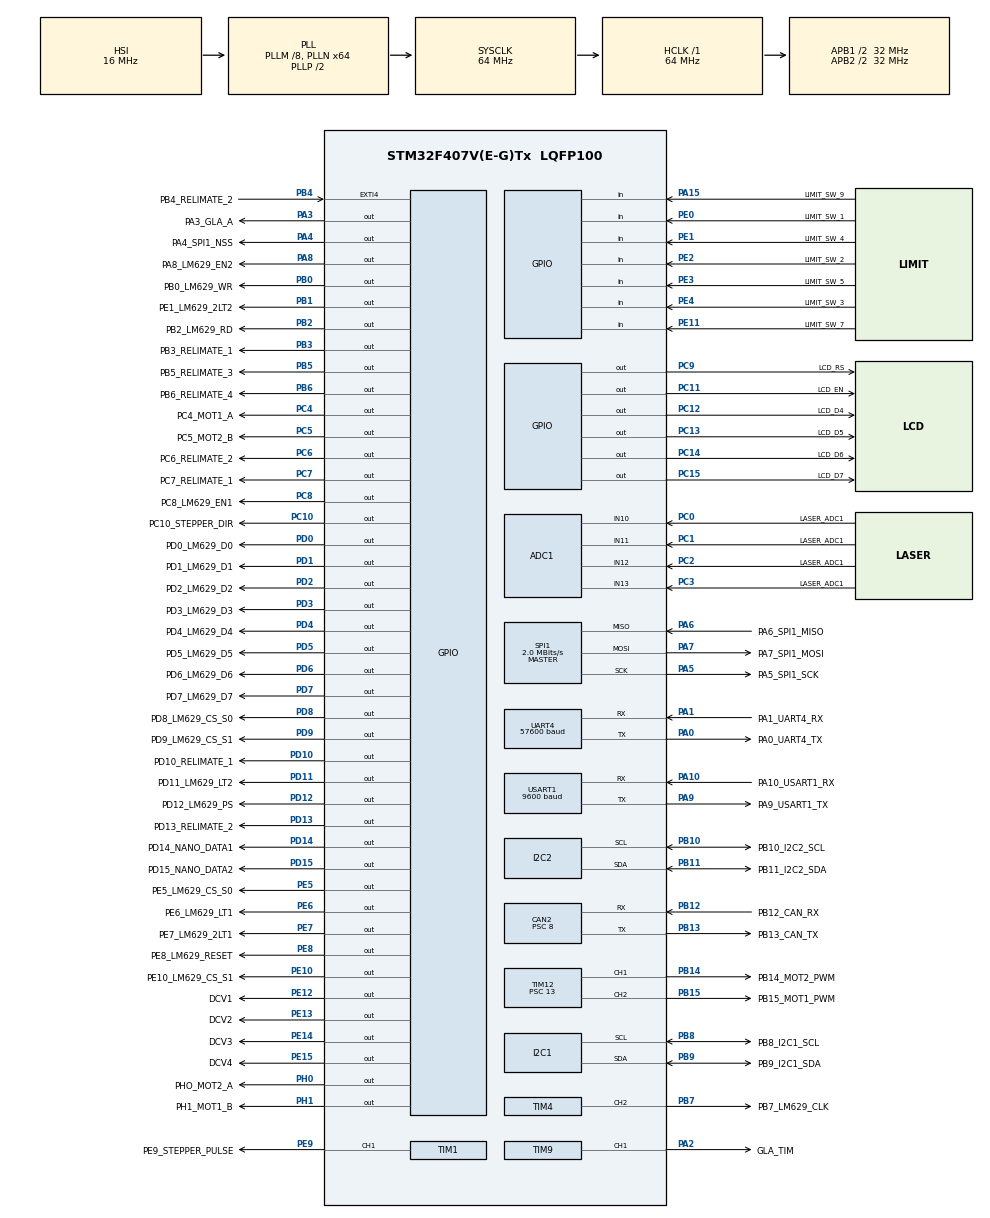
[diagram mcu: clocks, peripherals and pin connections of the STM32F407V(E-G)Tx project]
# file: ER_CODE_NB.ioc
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ADC1.Channel-4\#ChannelRegularConversion=ADC_CHANNEL_10
ADC1.Channel-5\#ChannelRegularConversion=ADC_CHANNEL_10
ADC1.Channel-6\#ChannelRegularConversion=ADC_CHANNEL_10
ADC1.NbrOfConversion=3
ADC1.NbrOfConversionFlag=1
ADC1.Rank-4\#ChannelRegularConversion=1
ADC1.Rank-5\#ChannelRegularConversion=2
ADC1.Rank-6\#ChannelRegularConversion=3
ADC1.SamplingTime-4\#ChannelRegularConversion=ADC_SAMPLETIME_3CYCLES
ADC1.SamplingTime-5\#ChannelRegularConversion=ADC_SAMPLETIME_3CYCLES
ADC1.SamplingTime-6\#ChannelRegularConversion=ADC_SAMPLETIME_3CYCLES
ADC1.ScanConvMode=ENABLE
ADC1.master=1
CAN2.BS1=CAN_BS1_13TQ
CAN2.BS2=CAN_BS2_2TQ
CAN2.CalculateBaudRate=250000
CAN2.CalculateTimeBit=4000
CAN2.CalculateTimeQuantum=250.0
CAN2.Prescaler=8
Dma.Request0=UART4_RX
Dma.Request1=UART4_TX
Dma.UART4_RX.0.Direction=DMA_PERIPH_TO_MEMORY
Dma.UART4_RX.0.FIFOMode=DMA_FIFOMODE_DISABLE
Dma.UART4_RX.0.Instance=DMA1_Stream2
Dma.UART4_RX.0.MemDataAlignment=DMA_MDATAALIGN_BYTE
Dma.UART4_RX.0.MemInc=DMA_MINC_ENABLE
Dma.UART4_RX.0.Mode=DMA_NORMAL
Dma.UART4_RX.0.PeriphDataAlignment=DMA_PDATAALIGN_BYTE
Dma.UART4_RX.0.PeriphInc=DMA_PINC_DISABLE
Dma.UART4_RX.0.Priority=DMA_PRIORITY_LOW
Dma.UART4_TX.1.Direction=DMA_MEMORY_TO_PERIPH
Dma.UART4_TX.1.FIFOMode=DMA_FIFOMODE_DISABLE
Dma.UART4_TX.1.Instance=DMA1_Stream4
Dma.UART4_TX.1.MemDataAlignment=DMA_MDATAALIGN_BYTE
Dma.UART4_TX.1.MemInc=DMA_MINC_ENABLE
Dma.UART4_TX.1.Mode=DMA_NORMAL
Dma.UART4_TX.1.PeriphDataAlignment=DMA_PDATAALIGN_BYTE
Dma.UART4_TX.1.PeriphInc=DMA_PINC_DISABLE
Dma.UART4_TX.1.Priority=DMA_PRIORITY_LOW
I2C2.I2C_Mode=I2C_Fast
Mcu.Family=STM32F4
Mcu.Name=STM32F407V(E-G)Tx
Mcu.Package=LQFP100
NVIC.DMA1_Stream2_IRQn=true\:0\:0\:false\:false\:true\:false\:true\:true
NVIC.DMA1_Stream4_IRQn=true\:0\:0\:false\:false\:true\:false\:true\:true
NVIC.PriorityGroup=NVIC_PRIORITYGROUP_4
NVIC.USART1_IRQn=true\:0\:0\:false\:false\:true\:true\:true\:true
PA0-WKUP.GPIO_Label=PA0_UART4_TX
PA0-WKUP.Mode=Asynchronous
PA0-WKUP.Signal=UART4_TX
PA1.GPIO_Label=PA1_UART4_RX
PA1.Mode=Asynchronous
PA1.Signal=UART4_RX
PA10.GPIO_Label=PA10_USART1_RX
PA10.Mode=Asynchronous
PA10.Signal=USART1_RX
PA13.Mode=Serial_Wire
PA13.Signal=SYS_JTMS-SWDIO
PA14.Mode=Serial_Wire
PA14.Signal=SYS_JTCK-SWCLK
PA15.GPIO_Label=LIMIT_SW_9
PA15.Signal=GPIO_Input
PA2.GPIO_Label=GLA_TIM
PA2.Signal=S_TIM9_CH1
PA3.GPIO_Label=PA3_GLA_A
PA3.Signal=GPIO_Output
PA4.GPIO_Label=PA4_SPI1_NSS
PA4.Signal=GPIO_Output
PA5.GPIO_Label=PA5_SPI1_SCK
PA5.Mode=Full_Duplex_Master
PA5.Signal=SPI1_SCK
PA6.GPIO_Label=PA6_SPI1_MISO
PA6.Mode=Full_Duplex_Master
PA6.Signal=SPI1_MISO
PA7.GPIO_Label=PA7_SPI1_MOSI
PA7.Mode=Full_Duplex_Master
PA7.Signal=SPI1_MOSI
PA8.GPIO_Label=PA8_LM629_EN2
PA8.Signal=GPIO_Output
PA9.GPIO_Label=PA9_USART1_TX
PA9.Mode=Asynchronous
PA9.Signal=USART1_TX
PB0.GPIO_Label=PB0_LM629_WR
PB0.Signal=GPIO_Output
PB1.GPIO_Label=PE1_LM629_2LT2
PB1.Signal=GPIO_Output
PB10.GPIO_Label=PB10_I2C2_SCL
PB10.Mode=I2C
PB10.Signal=I2C2_SCL
PB11.GPIO_Label=PB11_I2C2_SDA
PB11.Mode=I2C
PB11.Signal=I2C2_SDA
PB12.GPIO_Label=PB12_CAN_RX
PB12.Mode=CAN_Activate
PB12.Signal=CAN2_RX
PB13.GPIO_Label=PB13_CAN_TX
PB13.Mode=CAN_Activate
PB13.Signal=CAN2_TX
PB14.GPIO_Label=PB14_MOT2_PWM
PB14.Signal=S_TIM12_CH1
PB15.GPIO_Label=PB15_MOT1_PWM
PB15.Signal=S_TIM12_CH2
PB2.GPIO_Label=PB2_LM629_RD
PB2.Signal=GPIO_Output
PB3.GPIO_Label=PB3_RELIMATE_1
PB3.Signal=GPIO_Output
PB4.GPIO_Label=PB4_RELIMATE_2
PB4.Signal=GPXTI4
PB5.GPIO_Label=PB5_RELIMATE_3
PB5.Signal=GPIO_Output
PB6.GPIO_Label=PB6_RELIMATE_4
PB6.Signal=GPIO_Output
PB7.GPIO_Label=PB7_LM629_CLK
PB7.Signal=S_TIM4_CH2
PB8.GPIO_Label=PB8_I2C1_SCL
PB8.Mode=I2C
PB8.Signal=I2C1_SCL
PB9.GPIO_Label=PB9_I2C1_SDA
PB9.Mode=I2C
PB9.Signal=I2C1_SDA
PC0.GPIO_Label=LASER_ADC1
PC0.Signal=ADCx_IN10
PC1.GPIO_Label=LASER_ADC1
PC1.Signal=ADCx_IN11
PC10.GPIO_Label=PC10_STEPPER_DIR
PC10.Signal=GPIO_Output
PC11.GPIO_Label=LCD_EN
PC11.Signal=GPIO_Output
PC12.GPIO_Label=LCD_D4
PC12.Signal=GPIO_Output
PC13-ANTI_TAMP.GPIO_Label=LCD_D5
PC13-ANTI_TAMP.Signal=GPIO_Output
PC14-OSC32_IN.GPIO_Label=LCD_D6
PC14-OSC32_IN.Signal=GPIO_Output
PC15-OSC32_OUT.GPIO_Label=LCD_D7
PC15-OSC32_OUT.Signal=GPIO_Output
PC2.GPIO_Label=LASER_ADC1
PC2.Signal=ADCx_IN12
PC3.GPIO_Label=LASER_ADC1
PC3.Signal=ADCx_IN13
PC4.GPIO_Label=PC4_MOT1_A
PC4.Signal=GPIO_Output
PC5.GPIO_Label=PC5_MOT2_B
PC5.Signal=GPIO_Output
PC6.GPIO_Label=PC6_RELIMATE_2
PC6.Signal=GPIO_Output
PC7.GPIO_Label=PC7_RELIMATE_1
PC7.Signal=GPIO_Output
PC8.GPIO_Label=PC8_LM629_EN1
PC8.Signal=GPIO_Output
PC9.GPIO_Label=LCD_RS
PC9.Signal=GPIO_Output
PD0.GPIO_Label=PD0_LM629_D0
PD0.Signal=GPIO_Output
PD1.GPIO_Label=PD1_LM629_D1
PD1.Signal=GPIO_Output
PD10.GPIO_Label=PD10_RELIMATE_1
PD10.Signal=GPIO_Output
PD11.GPIO_Label=PD11_LM629_LT2
PD11.Signal=GPIO_Output
PD12.GPIO_Label=PD12_LM629_PS
PD12.Signal=GPIO_Output
PD13.GPIO_Label=PD13_RELIMATE_2
PD13.Signal=GPIO_Output
PD14.GPIO_Label=PD14_NANO_DATA1
PD14.Signal=GPIO_Output
PD15.GPIO_Label=PD15_NANO_DATA2
PD15.Signal=GPIO_Output
PD2.GPIO_Label=PD2_LM629_D2
PD2.Signal=GPIO_Output
PD3.GPIO_Label=PD3_LM629_D3
PD3.Signal=GPIO_Output
PD4.GPIO_Label=PD4_LM629_D4
PD4.Signal=GPIO_Output
PD5.GPIO_Label=PD5_LM629_D5
PD5.Signal=GPIO_Output
PD6.GPIO_Label=PD6_LM629_D6
PD6.Signal=GPIO_Output
PD7.GPIO_Label=PD7_LM629_D7
PD7.Signal=GPIO_Output
PD8.GPIO_Label=PD8_LM629_CS_S0
PD8.Signal=GPIO_Output
PD9.GPIO_Label=PD9_LM629_CS_S1
PD9.Signal=GPIO_Output
PE0.GPIO_Label=LIMIT_SW_1
PE0.Signal=GPIO_Input
PE1.GPIO_Label=LIMIT_SW_4
PE1.Signal=GPIO_Input
PE10.GPIO_Label=PE10_LM629_CS_S1
PE10.Signal=GPIO_Output
PE11.GPIO_Label=LIMIT_SW_7
PE11.Signal=GPIO_Input
PE12.GPIO_Label=DCV1
PE12.Signal=GPIO_Output
PE13.GPIO_Label=DCV2
PE13.Signal=GPIO_Output
PE14.GPIO_Label=DCV3
PE14.Signal=GPIO_Output
PE15.GPIO_Label=DCV4
PE15.Signal=GPIO_Output
PE2.GPIO_Label=LIMIT_SW_2
PE2.Signal=GPIO_Input
PE3.GPIO_Label=LIMIT_SW_5
PE3.Signal=GPIO_Input
PE4.GPIO_Label=LIMIT_SW_3
PE4.Signal=GPIO_Input
PE5.GPIO_Label=PE5_LM629_CS_S0
PE5.Signal=GPIO_Output
PE6.GPIO_Label=PE6_LM629_LT1
PE6.Signal=GPIO_Output
PE7.GPIO_Label=PE7_LM629_2LT1
PE7.Signal=GPIO_Output
PE8.GPIO_Label=PE8_LM629_RESET
PE8.Signal=GPIO_Output
PE9.GPIO_Label=PE9_STEPPER_PULSE
PE9.Signal=S_TIM1_CH1
PH0-OSC_IN.GPIO_Label=PHO_MOT2_A
PH0-OSC_IN.Signal=GPIO_Output
PH1-OSC_OUT.GPIO_Label=PH1_MOT1_B
PH1-OSC_OUT.Signal=GPIO_Output
ProjectManager.HeapSize=0x200
ProjectManager.StackSize=0x400
ProjectManager.TargetToolchain=STM32CubeIDE
RCC.48MHZClocksFreq_Value=32000000
RCC.AHBFreq_Value=64000000
RCC.APB1CLKDivider=RCC_HCLK_DIV2
RCC.APB1Freq_Value=32000000
RCC.APB1TimFreq_Value=64000000
RCC.APB2CLKDivider=RCC_HCLK_DIV2
RCC.APB2Freq_Value=32000000
RCC.APB2TimFreq_Value=64000000
RCC.CortexFreq_Value=64000000
RCC.HCLKFreq_Value=64000000
RCC.HSE_VALUE=25000000
RCC.HSI_VALUE=16000000
RCC.LSE_VALUE=32768
RCC.PLLM=8
RCC.PLLN=64
RCC.SYSCLKFreq_VALUE=64000000
RCC.SYSCLKSource=RCC_SYSCLKSOURCE_PLLCLK
RCC.VCOOutputFreq_Value=128000000
SH.ADCx_IN10.0=ADC1_IN10,IN10
SH.ADCx_IN11.0=ADC1_IN11,IN11
SH.ADCx_IN12.0=ADC1_IN12,IN12
SH.ADCx_IN13.0=ADC1_IN13,IN13
SH.S_TIM12_CH1.0=TIM12_CH1,PWM Generation1 CH1
SH.S_TIM12_CH2.0=TIM12_CH2,PWM Generation2 CH2
SH.S_TIM1_CH1.0=TIM1_CH1,PWM Generation1 CH1
SH.S_TIM4_CH2.0=TIM4_CH2,Output Compare2 CH2
SH.S_TIM9_CH1.0=TIM9_CH1,PWM Generation1 CH1
SPI1.BaudRatePrescaler=SPI_BAUDRATEPRESCALER_16
SPI1.CalculateBaudRate=2.0 MBits/s
SPI1.Direction=SPI_DIRECTION_2LINES
SPI1.Mode=SPI_MODE_MASTER
SPI1.VirtualType=VM_MASTER
TIM1.Channel-PWM\ Generation1\ CH1=TIM_CHANNEL_1
TIM1.Period=255
TIM1.Prescaler=13
TIM12.Channel-PWM\ Generation1\ CH1=TIM_CHANNEL_1
TIM12.Channel-PWM\ Generation2\ CH2=TIM_CHANNEL_2
TIM12.Period=255
TIM12.Prescaler=13
TIM4.Channel-Output\ Compare2\ CH2=TIM_CHANNEL_2
TIM4.OCMode_2=TIM_OCMODE_TOGGLE
TIM4.Period=7
TIM7.Prescaler=7
TIM9.Channel-PWM\ Generation1\ CH1=TIM_CHANNEL_1
TIM9.Period=255
TIM9.Prescaler=13
UART4.BaudRate=57600
UART4.VirtualMode=Asynchronous
USART1.BaudRate=9600
USART1.VirtualMode=VM_ASYNC
VP_TIM7_VS_ClockSourceINT.Mode=Enable_Timer
board=custom

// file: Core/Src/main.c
/* USER CODE BEGIN Header */
/**
 ******************************************************************************
 * @file           : main.c
 * @brief          : Main program body
 ******************************************************************************
 * @attention
 *
 * Copyright (c) 2023 STMicroelectronics.
 * All rights reserved.
 *
 * This software is licensed under terms that can be found in the LICENSE file
 * in the root directory of this software component.
 * If no LICENSE file comes with this software, it is provided AS-IS.
 *
 ******************************************************************************
 */
/* USER CODE END Header */
#include "main.h"
#include "adc.h"
#include "can.h"
#include "dma.h"
#include "i2c.h"
#include "spi.h"
#include "tim.h"
#include "usart.h"
#include "gpio.h"

/* USER CODE BEGIN Includes */
#include "init.h"
/* USER CODE END Includes */

void SystemClock_Config(void);

int main(void)
{

	/* MCU Configuration--------------------------------------------------------*/

	/* Reset of all peripherals, Initializes the Flash interface and the Systick. */
	HAL_Init();

	/* Configure the system clock */
	SystemClock_Config();

	/* Initialize all configured peripherals */
	MX_GPIO_Init();
	MX_DMA_Init();
	MX_UART4_Init();
	MX_USART1_UART_Init();
	MX_ADC1_Init();
	MX_CAN2_Init();
	MX_I2C1_Init();
	MX_I2C2_Init();
	MX_SPI1_Init();
	MX_TIM4_Init();
	MX_TIM12_Init();
	MX_TIM1_Init();
	MX_TIM7_Init();
	MX_TIM9_Init();
	/* USER CODE BEGIN 2 */
	int accnf = 600;
	delay_init(DELAY_MODULE);
	lm629_clock_start(LM629_CLOCK_MODULE);
	motors_pwm_start(MOTOR_MODULE);
	//	encoders_init();
	adc_init();
	mux_auto();
	lcd_init();
	// CAN_filterConfig();
	// HAL_CAN_Start(&hcan2);
	//	servo_pwm_start(BLDC_TIM_MODULE);
	int q, tick, dt, prev_tick, pd;
	int ps4_mode = 0;
	int st = 0;
	int pickmode = 0;
	int mode = 0;
	int limit_value1 = 0;
	int limit_value4 = 0;
	int limit_value3 = 0;
	int limit_value2 = 0;
	char *buffer1[1];
	int ret;
	int stop = 0;
	int j = 800;
	int steppermode = 0;

	lcd_gotoxy(1, 1);
	lcd_string("Robocon 2023");
	HAL_Delay(800);
	lcd_clear();

	int status = 0;
	//		encoders_define_home();
	lcd_clear();
	lcd_gotoxy(1, 1);
	lcd_string("Homed");
	HAL_Delay(800);
	lcd_clear();
	lcd_clear();
	float x = 0;
	float y = 0;

	int prev_distance = 0;
	/////////////////////
	//	    robot_position_init(50,50);
	robot_velocity_init(accnf);
	lcd_clear();
	lcd_gotoxy(1, 1);
	lcd_string("Velocity init done");
	HAL_Delay(800);
	lcd_clear();

	while (pairing_flag == false)
	{
		lcd_gotoxy(4, 1);
		connect_ps4();
		lcd_gotoxy(1, 4);
		lcd_string("Pair Lost");
	}
	lcd_clear();

	stick_invert_flag = false;

	/* USER CODE END 2 */

	/* Infinite loop */
	/* USER CODE BEGIN WHILE */
	while (0)
	{
		VELOCITY_MAX_SPEED = 350;
		receive_ps4();
		lcd_print(1, 1, read_real_position(1), 5);
		lcd_print(2, 1, read_real_position(2), 5);
		lcd_print(3, 1, read_real_position(3), 5);
		lcd_print(4, 1, read_real_position(4), 5);

		lcd_print(4, 10, HAL_GPIO_ReadPin(LIMIT_SW_1_GPIO_Port, LIMIT_SW_1_Pin), 1);
		lcd_print(4, 11, HAL_GPIO_ReadPin(LIMIT_SW_2_GPIO_Port, LIMIT_SW_2_Pin), 1);
		lcd_print(4, 12, HAL_GPIO_ReadPin(LIMIT_SW_3_GPIO_Port, LIMIT_SW_3_Pin), 1);
		lcd_print(4, 13, HAL_GPIO_ReadPin(LIMIT_SW_4_GPIO_Port, LIMIT_SW_4_Pin), 1);
		lcd_print(4, 14, HAL_GPIO_ReadPin(LIMIT_SW_5_GPIO_Port, LIMIT_SW_5_Pin), 1);
		lcd_print(4, 15, HAL_GPIO_ReadPin(LIMIT_SW_7_GPIO_Port, LIMIT_SW_7_Pin), 1);
		lcd_print(4, 16, HAL_GPIO_ReadPin(LIMIT_SW_9_GPIO_Port, LIMIT_SW_9_Pin), 1);
		lcd_print(3, 10, j, 4);

		//	  if (PS4_L1_PRESSED)
		//	  		{
		//		  	  	  robot_newvelocity_run(100, 0, 0, SMOOTH_STOP);
		//	  		}
		//	  if (PS4_L2_PRESSED)
		//	  		{
		//		  	  	  robot_newvelocity_run(0, 0, 0, SMOOTH_STOP);
		//	  		}
		//	  if (PS4_R1_PRESSED)
		//			{
		//				  robot_newvelocity_run(100, 90, 0, SMOOTH_STOP);
		//			}
		//	  if (PS4_R2_PRESSED)
		//			{
		//				  robot_newvelocity_run(0, 0, 45, SMOOTH_STOP);
		//			}
		//	  if (PS4_CROSS_PRESSED)
		//	  			{
		//	  				  robot_newvelocity_run(100,180, 0, SMOOTH_STOP);
		//	  			}
		robot_joystick_velocity();
		SAVE_CONSOLE;
	}
	while (1)
	{
		/* USER CODE END WHILE */

		/* USER CODE BEGIN 3 */

		/////////////////////////

		/////////////////////////

		receive_ps4();
		lcd_print(1, 1, read_real_position(1), 5);
		lcd_print(2, 1, read_real_position(2), 5);
		lcd_print(3, 1, read_real_position(3), 5);
		lcd_print(4, 1, read_real_position(4), 5);

		lcd_print(4, 10, HAL_GPIO_ReadPin(LIMIT_SW_1_GPIO_Port, LIMIT_SW_1_Pin), 1);
		lcd_print(4, 11, HAL_GPIO_ReadPin(LIMIT_SW_2_GPIO_Port, LIMIT_SW_2_Pin), 1);
		lcd_print(4, 12, HAL_GPIO_ReadPin(LIMIT_SW_3_GPIO_Port, LIMIT_SW_3_Pin), 1);
		lcd_print(4, 13, HAL_GPIO_ReadPin(LIMIT_SW_4_GPIO_Port, LIMIT_SW_4_Pin), 1);
		lcd_print(4, 14, HAL_GPIO_ReadPin(LIMIT_SW_5_GPIO_Port, LIMIT_SW_5_Pin), 1);
		lcd_print(4, 15, HAL_GPIO_ReadPin(LIMIT_SW_7_GPIO_Port, LIMIT_SW_7_Pin), 1);
		lcd_print(4, 16, HAL_GPIO_ReadPin(LIMIT_SW_9_GPIO_Port, LIMIT_SW_9_Pin), 1);
		lcd_print(3, 10, j, 4);

		if (HAL_GPIO_ReadPin(GPIOA, GPIO_PIN_10) == 1)
		{
			st = 0;
		}
		if (st > 19)
		{
			st = 19;
		}
		if (st < 0)
		{
			st = 0;
		}

		if (PS4_CROSS_PRESSED)
		{
			robot_velocity_init(accnf);
			lcd_clear();
			lcd_gotoxy(1, 1);
			lcd_string("Velocity INIT Done");
			HAL_Delay(800);
			lcd_clear();
			lcd_print(1, 1, read_real_position(1), 5);
			lcd_print(2, 1, read_real_position(2), 5);
			lcd_print(3, 1, read_real_position(3), 5);
			lcd_print(4, 1, read_real_position(4), 5);

			lcd_print(4, 10, HAL_GPIO_ReadPin(LIMIT_SW_1_GPIO_Port, LIMIT_SW_1_Pin), 1);
			lcd_print(4, 11, HAL_GPIO_ReadPin(LIMIT_SW_2_GPIO_Port, LIMIT_SW_2_Pin), 1);
			lcd_print(4, 12, HAL_GPIO_ReadPin(LIMIT_SW_3_GPIO_Port, LIMIT_SW_3_Pin), 1);
			lcd_print(4, 13, HAL_GPIO_ReadPin(LIMIT_SW_4_GPIO_Port, LIMIT_SW_4_Pin), 1);
			lcd_print(4, 14, HAL_GPIO_ReadPin(LIMIT_SW_5_GPIO_Port, LIMIT_SW_5_Pin), 1);
			lcd_print(3, 10, j, 4);
		}
		//////////////  BD Mode
		if (PS4_L1_PRESSED)
		{
			VELOCITY_MAX_SPEED = 100;
		}

		if (PS4_L1_RELEASED)
		{
			VELOCITY_MAX_SPEED = 400;
		}

		if (PS4_OPTIONS_PRESSED)
		{
			ps4_mode = !(ps4_mode);
			lcd_print(4, 17, ps4_mode, 1);
		}
		if (pickmode == 1)
		{

			if (HAL_GPIO_ReadPin(LIMIT_SW_7_GPIO_Port, LIMIT_SW_7_Pin) == 1)
			{
				mode = 1;
			}
			if (HAL_GPIO_ReadPin(LIMIT_SW_5_GPIO_Port, LIMIT_SW_5_Pin) == 1)
			{
				mode = 0;
			}
			if (HAL_GPIO_ReadPin(LIMIT_SW_1_GPIO_Port, LIMIT_SW_1_Pin) == 1)
			{
				if (mode == 0)
				{
					limit_value1 = 100;
				}
				else
				{
					limit_value1 = 250; // 160
				}
			}
			else
			{
				limit_value1 = 10;
			}

			motor_fwd(ELBOW, limit_value1);
			if (HAL_GPIO_ReadPin(LIMIT_SW_3_GPIO_Port, LIMIT_SW_3_Pin) == 1)
			{
				limit_value4 = 80;
			}
			else
			{
				pickmode = 0;
				limit_value4 = 0;
			}
			motor_rev(SHOULDER, limit_value4);
		}

		if (ps4_mode == 0) // RING PICKING MODE
		{

			////////TURN TABLE   --  SQUARE, CIRCLE
			if (PS4_SQUARE)
			{

				if (HAL_GPIO_ReadPin(LIMIT_SW_3_GPIO_Port, LIMIT_SW_3_Pin) == 0)
				{
					limit_value3 = 100;
				}
				else
				{
					limit_value3 = 0;
				}

				motor_fwd(SHOULDER, limit_value3);
			}
			if (PS4_SQUARE_RELEASED)
			{

				motor_fwd(SHOULDER, 0);
			}

			if (PS4_CIRCLE)
			{

				if (HAL_GPIO_ReadPin(LIMIT_SW_4_GPIO_Port, LIMIT_SW_4_Pin) == 0)
				{
					limit_value4 = 120;
				}
				else
				{
					limit_value4 = 0;
				}
				motor_rev(SHOULDER, limit_value4);
			}
			if (PS4_CIRCLE_RELEASED)
			{

				motor_rev(SHOULDER, 0);
			}
			///////////////////////////////////////////////////////////////////////////
			if (PS4_L1)
			{
				// Turn Table
				if (PS4_SQUARE)
				{
					motor_fwd(SHOULDER, 100);
				}
				if (PS4_SQUARE_RELEASED)
				{
					motor_fwd(SHOULDER, 0);
				}

				if (PS4_CIRCLE)
				{
					motor_rev(SHOULDER, 120);
				}
				if (PS4_CIRCLE_RELEASED)
				{
					motor_rev(SHOULDER, 0);
				}

				// Side Tower
				if (PS4_PAD_UP)
				{
					motor_fwd(ELBOW, 150);
				}
				if (PS4_PAD_UP_RELEASED)
				{
					motor_fwd(ELBOW, 0);
				}
				if (PS4_PAD_DOWN)
				{
					motor_rev(ELBOW, 70);
				}
				if (PS4_PAD_DOWN_RELEASED)
				{
					motor_rev(ELBOW, 0);
				}
			}

			if (PS4_TOUCHPAD_PRESSED) // SIDE TOWER GRIPPER
			{
				HAL_GPIO_TogglePin(DCV2_GPIO_Port, DCV2_Pin);
				HAL_Delay(100);
			}

			if (PS4_TRIANGLE_PRESSED) // SIDE TOWER UP DOWN
			{
				HAL_GPIO_TogglePin(DCV3_GPIO_Port, DCV3_Pin);
			}
			if (PS4_PAD_LEFT_PRESSED) // SIDE TOWER UP DOWN
			{
				HAL_GPIO_TogglePin(DCV4_GPIO_Port, DCV4_Pin);
			}

			////////// SIDE TOWER  -- PAD_UP(up), PAD_DOWN(down) with limit switch

			if (PS4_PAD_UP)
			{
				//				limit_value1 = 100;

				if (HAL_GPIO_ReadPin(LIMIT_SW_1_GPIO_Port, LIMIT_SW_1_Pin) == 0)
				{
					limit_value1 = 150;
				}
				else
				{
					limit_value1 = 30;
				}

				motor_fwd(ELBOW, limit_value1);
			}
			if (PS4_PAD_UP_RELEASED)
			{

				motor_fwd(ELBOW, 0);
			}
			if (PS4_PAD_DOWN)
			{

				if (HAL_GPIO_ReadPin(LIMIT_SW_2_GPIO_Port, LIMIT_SW_2_Pin) == 1)
				{

					limit_value2 = 70;
				}
				else
				{
					limit_value2 = 0;
				}
				motor_rev(ELBOW, limit_value2);
			}
			if (PS4_PAD_DOWN_RELEASED)
			{

				motor_rev(ELBOW, 0);
			}
		}

		if (ps4_mode == 1) // RING SHOOTING MODE
		{
			if (PS4_L1)
			{
				steppermode = 1;
			}
			else
			{
				steppermode = 0;
			}

			if (steppermode == 0)
			{
				if (PS4_PAD_DOWN_PRESSED && (HAL_GPIO_ReadPin(LIMIT_SW_5_GPIO_Port, LIMIT_SW_5_Pin) == 0))
				{
					st--;
					//				if(st >= 0){
					buffer1[0] = '2';
					ret = HAL_I2C_Master_Transmit(&hi2c1, 4 << 1, (uint8_t *)buffer1, 1, 100);
					lcd_gotoxy(1, 10);
					lcd_string("Down");
					//				}
				}
				else if (PS4_PAD_DOWN_RELEASED)
				{
					buffer1[0] = 'a';
					ret = HAL_I2C_Master_Transmit(&hi2c1, 4 << 1, (uint8_t *)buffer1, 1, 100);
				}
				if (PS4_PAD_UP_PRESSED)
				{
					st++;
					//				if(st <= 19){
					buffer1[0] = '1';
					ret = HAL_I2C_Master_Transmit(&hi2c1, 4 << 1, (uint8_t *)buffer1, 1, 100);
					lcd_gotoxy(1, 10);
					lcd_string("Up");
					//				}
				}
				else if (PS4_PAD_UP_RELEASED)
				{
					buffer1[0] = 'a';
					ret = HAL_I2C_Master_Transmit(&hi2c1, 4 << 1, (uint8_t *)buffer1, 1, 100);
				}
			}
			if (steppermode == 1)
			{
				if (PS4_PAD_DOWN_PRESSED && (HAL_GPIO_ReadPin(LIMIT_SW_5_GPIO_Port, LIMIT_SW_5_Pin) == 0))
				{
					st--;
					//				if(st >= 0){
					buffer1[0] = '6';
					ret = HAL_I2C_Master_Transmit(&hi2c1, 4 << 1, (uint8_t *)buffer1, 1, 100);
					lcd_gotoxy(1, 10);
					lcd_string("Down");
					//				}
				}
				else if (PS4_PAD_DOWN_RELEASED)
				{
					buffer1[0] = 'a';
					ret = HAL_I2C_Master_Transmit(&hi2c1, 4 << 1, (uint8_t *)buffer1, 1, 100);
				}
				if (PS4_PAD_UP_PRESSED)
				{
					st++;
					//				if(st <= 19){
					buffer1[0] = '5';
					ret = HAL_I2C_Master_Transmit(&hi2c1, 4 << 1, (uint8_t *)buffer1, 1, 100);
					lcd_gotoxy(1, 10);
					lcd_string("Up");
					//				}
				}
				else if (PS4_PAD_UP_RELEASED)
				{
					buffer1[0] = 'a';
					ret = HAL_I2C_Master_Transmit(&hi2c1, 4 << 1, (uint8_t *)buffer1, 1, 100);
				}
			}
			/////////  GLA  --  PAD-LEFT, PAD-RIGHT
			if (PS4_PAD_RIGHT)
			{
				motor_fwd(GLA_MOTOR, 240);
			}
			if (PS4_PAD_RIGHT_RELEASED)
			{
				motor_fwd(GLA_MOTOR, 0);
			}
			if (PS4_PAD_LEFT)
			{
				motor_rev(GLA_MOTOR, 240);
			}
			if (PS4_PAD_LEFT_RELEASED)
			{
				motor_rev(GLA_MOTOR, 0);
			}

			//////// DCV   --   OPTIONS, SHARE
			if (PS4_TOUCHPAD_PRESSED) // RING PUSHING MECHANISM
			{
				HAL_GPIO_TogglePin(DCV1_GPIO_Port, DCV1_Pin);
				HAL_Delay(500);
				HAL_GPIO_TogglePin(DCV1_GPIO_Port, DCV1_Pin);
				HAL_Delay(500);
				buffer1[0] = '1';
				ret = HAL_I2C_Master_Transmit(&hi2c1, 4 << 1, (uint8_t *)buffer1, 1, 100);
				lcd_gotoxy(1, 10);
				lcd_string("Up");
				buffer1[0] = 'a';
				ret = HAL_I2C_Master_Transmit(&hi2c1, 4 << 1, (uint8_t *)buffer1, 1, 100);
				st++;
				//				if(st <= 19){
				//					buffer1[0] = '1';
				//				}
			}
			//			else if (PS4_TOUCHPAD_RELEASED){
			//				buffer1[0] = 'a';
			//			}

			///////BLDC  --  PAD-UP-&-L1, PAD-DOWN-&-L2

			if (PS4_L2)
			{
				if (PS4_R1_PRESSED)
				{
					buffer1[0] = 'd';
					ret = HAL_I2C_Master_Transmit(&hi2c1, 4 << 1, (uint8_t *)buffer1, 1, 100);
					j += 2;
				}
				else if (PS4_R1_RELEASED)
				{
					buffer1[0] = 'a';
					ret = HAL_I2C_Master_Transmit(&hi2c1, 4 << 1, (uint8_t *)buffer1, 1, 100);
				}
				if (PS4_R2_PRESSED)
				{
					buffer1[0] = 'e';
					ret = HAL_I2C_Master_Transmit(&hi2c1, 4 << 1, (uint8_t *)buffer1, 1, 100);
					j -= 2;
				}
				else if (PS4_R2_RELEASED)
				{
					buffer1[0] = 'a';
					ret = HAL_I2C_Master_Transmit(&hi2c1, 4 << 1, (uint8_t *)buffer1, 1, 100);
				}
			}
			else
			{
				if (PS4_R1_PRESSED)
				{
					buffer1[0] = 'b';
					ret = HAL_I2C_Master_Transmit(&hi2c1, 4 << 1, (uint8_t *)buffer1, 1, 100);
					j += 5;
				}
				else if (PS4_R1_RELEASED)
				{
					buffer1[0] = 'a';
					ret = HAL_I2C_Master_Transmit(&hi2c1, 4 << 1, (uint8_t *)buffer1, 1, 100);
				}
				if (PS4_R2_PRESSED)
				{
					buffer1[0] = 'c';
					ret = HAL_I2C_Master_Transmit(&hi2c1, 4 << 1, (uint8_t *)buffer1, 1, 100);
					j -= 5;
				}
				else if (PS4_R2_RELEASED)
				{
					buffer1[0] = 'a';
					ret = HAL_I2C_Master_Transmit(&hi2c1, 4 << 1, (uint8_t *)buffer1, 1, 100);
				}
			}
			if (PS4_CIRCLE_PRESSED)
			{

				buffer1[0] = 'f';
				ret = HAL_I2C_Master_Transmit(&hi2c1, 4 << 1, (uint8_t *)buffer1, 1, 100);
				j = 1045;
			}
			else if (PS4_CIRCLE_RELEASED)
			{
				buffer1[0] = 'a';
				ret = HAL_I2C_Master_Transmit(&hi2c1, 4 << 1, (uint8_t *)buffer1, 1, 100);
			}
			if (PS4_SQUARE_PRESSED)
			{
				buffer1[0] = 'g';
				ret = HAL_I2C_Master_Transmit(&hi2c1, 4 << 1, (uint8_t *)buffer1, 1, 100);
				j = 1000;
			}
			else if (PS4_SQUARE_RELEASED)
			{
				buffer1[0] = 'a';
				ret = HAL_I2C_Master_Transmit(&hi2c1, 4 << 1, (uint8_t *)buffer1, 1, 100);
			}
			if (PS4_TRIANGLE_PRESSED)
			{

				buffer1[0] = 'h';
				ret = HAL_I2C_Master_Transmit(&hi2c1, 4 << 1, (uint8_t *)buffer1, 1, 100);
				j = 800;
			}
			else if (PS4_TRIANGLE_RELEASED)
			{
				buffer1[0] = 'a';
				ret = HAL_I2C_Master_Transmit(&hi2c1, 4 << 1, (uint8_t *)buffer1, 1, 100);
			}

			////////// Stepper -- PAD_UP, PAD_DOWN, SHARE
			if (PS4_SHARE_PRESSED)
			{
				stop = 1;
				buffer1[0] = '3';
				ret = HAL_I2C_Master_Transmit(&hi2c1, 4 << 1, (uint8_t *)buffer1, 1, 100);
			}
			else if (PS4_SHARE_RELEASED)
			{
				buffer1[0] = 'a';
				ret = HAL_I2C_Master_Transmit(&hi2c1, 4 << 1, (uint8_t *)buffer1, 1, 100);
			}

			if (HAL_GPIO_ReadPin(LIMIT_SW_5_GPIO_Port, LIMIT_SW_5_Pin) == 1 && stop == 1)
			{
				buffer1[0] = '4';
				ret = HAL_I2C_Master_Transmit(&hi2c1, 4 << 1, (uint8_t *)buffer1, 1, 100);
				st = 0;
				stop = 0;
			}

			robot_joystick_velocity();
			SAVE_CONSOLE;
		}
	}
	/* USER CODE END 3 */
}

void SystemClock_Config(void)
{
	RCC_OscInitTypeDef RCC_OscInitStruct = {0};
	RCC_ClkInitTypeDef RCC_ClkInitStruct = {0};

	/** Configure the main internal regulator output voltage
	 */
	__HAL_RCC_PWR_CLK_ENABLE();
	__HAL_PWR_VOLTAGESCALING_CONFIG(PWR_REGULATOR_VOLTAGE_SCALE1);

	/** Initializes the RCC Oscillators according to the specified parameters
	 * in the RCC_OscInitTypeDef structure.
	 */
	RCC_OscInitStruct.OscillatorType = RCC_OSCILLATORTYPE_HSI;
	RCC_OscInitStruct.HSIState = RCC_HSI_ON;
	RCC_OscInitStruct.HSICalibrationValue = RCC_HSICALIBRATION_DEFAULT;
	RCC_OscInitStruct.PLL.PLLState = RCC_PLL_ON;
	RCC_OscInitStruct.PLL.PLLSource = RCC_PLLSOURCE_HSI;
	RCC_OscInitStruct.PLL.PLLM = 8;
	RCC_OscInitStruct.PLL.PLLN = 64;
	RCC_OscInitStruct.PLL.PLLP = RCC_PLLP_DIV2;
	RCC_OscInitStruct.PLL.PLLQ = 4;
	if (HAL_RCC_OscConfig(&RCC_OscInitStruct) != HAL_OK)
	{
		Error_Handler();
	}

	/** Initializes the CPU, AHB and APB buses clocks
	 */
	RCC_ClkInitStruct.ClockType = RCC_CLOCKTYPE_HCLK | RCC_CLOCKTYPE_SYSCLK | RCC_CLOCKTYPE_PCLK1 | RCC_CLOCKTYPE_PCLK2;
	RCC_ClkInitStruct.SYSCLKSource = RCC_SYSCLKSOURCE_PLLCLK;
	RCC_ClkInitStruct.AHBCLKDivider = RCC_SYSCLK_DIV1;
	RCC_ClkInitStruct.APB1CLKDivider = RCC_HCLK_DIV2;
	RCC_ClkInitStruct.APB2CLKDivider = RCC_HCLK_DIV2;

	if (HAL_RCC_ClockConfig(&RCC_ClkInitStruct, FLASH_LATENCY_2) != HAL_OK)
	{
		Error_Handler();
	}
}

void Error_Handler(void)
{
	__disable_irq();
	while (1)
	{
	}
}
